# Baikal-U register map
Vendor: BAIKAL ELECTRONICS, JSC; File version: 1.0
CPU: RISC-V r0p0, little endian, no MPU, no FPU, 3 interrupt priority bits
Registers are 32-bit, read-write, reset 0x0 unless marked. A register's access mark holds for its fields unless they carry their own. Offsets are from the block's base; [hi:lo] are bit positions; {n}, {i} and the like mark numbered series.

## AHB — Advanced High-performance Bus
Base 0x15108000
0x00 PL — Arbitration Priority Master n Register
  [3:0] PL — Arbitration priority for master
0x3C EBTCOUNT — Early Burst Termination Count Register
  [9:0] EBTCOUNT — Early burst termination count
0x40 EBT_EN — Early Burst Termination Enable Register
  [0] EBT_EN — Early burst termination enable
    0=DISABLE; 1=ENABLE
0x44 EBT — Early Burst Termination Register
  [0] EBT — Early burst termination
    0=DISABLE; 1=ENABLE
0x48 DFLT_MASTER — Default Master ID Number Register
  [3:0] DFLT_MASTER — Default master ID number
0x90 VERSION_ID — Component Version ID Register

## AXI — Advanced eXtensible Interface
Base 0x1400B000
0x400 VERSION_ID — Component Version ID Register
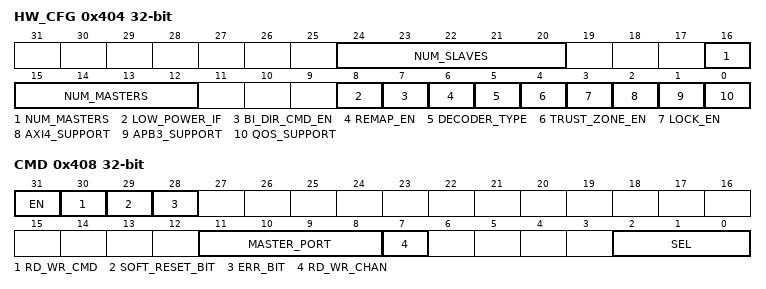
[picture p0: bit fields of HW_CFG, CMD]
0x404 HW_CFG — Hardware Configuration Register
  [24:20] NUM_SLAVES — Number of AXI slaves
  [16:12] NUM_MASTERS — Number of AXI masters
  [8] LOW_POWER_IF — Include/exclude low-power interface
    0=DISABLE; 1=ENABLE
  [7] BI_DIR_CMD_EN — Support for Enable Bi-directional Command
    0=DISABLE; 1=ENABLE
  [6] REMAP_EN — Support for Enable Remap mode
    0=DISABLE; 1=ENABLE
  [5] DECODER_TYPE — Use of External/Internal Decoder
    0=DISABLE; 1=ENABLE
  [4] TRUST_ZONE_EN — Support for Enable Trust Zone
    0=DISABLE; 1=ENABLE
  [3] LOCK_EN — Support for Enable Lock transactions
    0=DISABLE; 1=ENABLE
  [2] AXI4_SUPPORT — AXI4 features support
    0=DISABLE; 1=ENABLE
  [1] APB3_SUPPORT
    0=DISABLE; 1=ENABLE
  [0] QOS_SUPPORT
    0=DISABLE; 1=ENABLE
0x408 CMD — Command Enable Register
  [31] EN — Command enable
    0=DISABLE; 1=ENABLE
  [30] RD_WR_CMD — Read command / write command
    0=READ (Read command); 1=WRITE (Write command)
  [29] SOFT_RESET_BIT — Internal register reset
    0=DISABLE; 1=ENABLE
  [28] ERR_BIT — Error bit
    0=DISABLE; 1=ENABLE
  [11:8] MASTER_PORT — Master port ID
    {v}=Master port {v+1} (v=0..15)
  [7] RD_WR_CHAN — Read address channel / write address channel
    0=WRITE (The command is for write address channel); 1=READ (The command is for read address channel)
  [2:0] SEL — Command selection for internal registers
    0=BURST_REG_EN (BURSTINESS_REGULATOR_EN register address offset); 1=PEAK_RATE_XCT_RATE (PEAK_RATE_XCT_RATE register address offset); 2=QOS_VALUE (QOS_VALUE register address offset); 3=SLV_READY (SLV_READY register address offset)
0x40C DATA
  [31:0] DATA — Data to be written into / read from the QoS internal register

## EFLASH — Embedded Flash
Base 0xA0060000
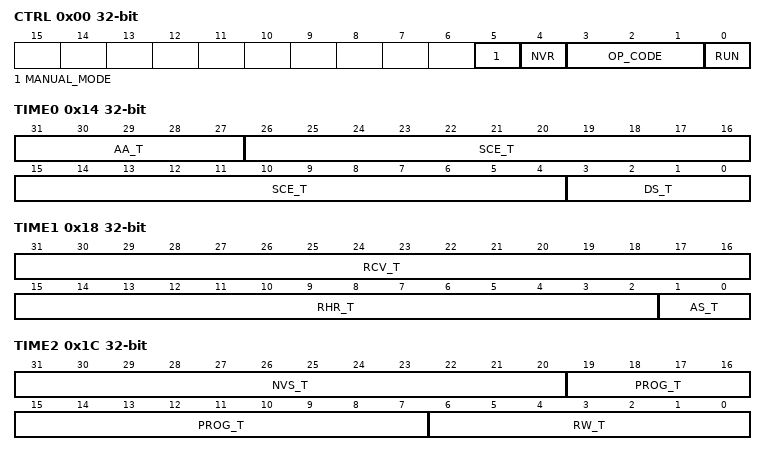
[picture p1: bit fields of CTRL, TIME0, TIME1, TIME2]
0x00 CTRL — Control register
  [5] MANUAL_MODE — Switch to manual control
    0=DISABLE; 1=ENABLE
  [4] NVR — Run OP_CODE in NVR array
    0=DISABLE; 1=ENABLE
  [3:1] OP_CODE — Operation code
    0=CFG (CFG: The flash memory configuration); 1=WRITE (WRITE: Write a word to the flash memory); 2=READ (READ: Read a word from the flash memory); 3=CHIP_ERASE (CHIP_ERASE: Chip erase); 4=BLOCK_ERASE (BLOCK_ERASE: Block erase); 5=SECTOR_ERASE (SECTOR_ERASE: Sector erase); 6=ENTER_DPD (ENTER_DPD: Enter Deep Power Down mode); 7=EXIT_DPD (EXIT_DPD: Exit Deep Power Down mode)
  [0] RUN — Run command
    0=DISABLE; 1=ENABLE
0x04 ADDR — Address register
  [15:0] ADDR — Address for a command
0x08 WDATA — Data write register
  [31:0] WDATA — Data to WRITE
0x0C RDATA — Data read register
  [31:0] RDATA — READ data
0x10 STATUS
  [0] BUSY — Busy flag
    0=DISABLE; 1=ENABLE
0x14 TIME0
  [31:27] AA_T — AE access time (max. 25ns)
  [26:4] SCE_T — Chip Erase time (8ms to 10ms)
  [3:0] DS_T — Data to PROG2 High setup time (min. 15ns)
0x18 TIME1
  [31:16] RCV_T — Erase recovery time (min. 50us)
  [15:2] RHR_T — PORb High to any operation time (min. 10us)
  [1:0] AS_T — Address and ARRDN/NVR setup time (min. 2ns)
0x1C TIME2
  [31:20] NVS_T — Program First AE / Sector Erase AE / Block Erase AE to WEb setup time (min. 4us)
  [19:7] PROG_T — Program time (8us to 10us)
  [6:0] RW_T — Latency to next operation after PROG/ERASE Low time (min. 100ns)
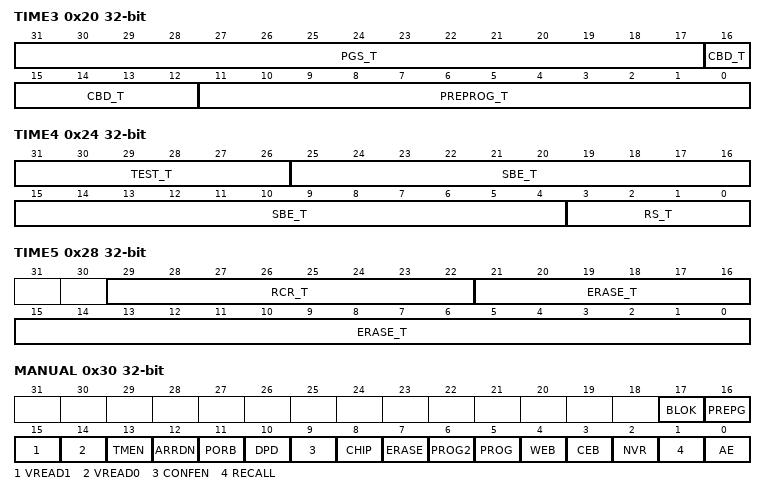
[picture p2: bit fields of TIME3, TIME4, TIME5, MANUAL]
0x20 TIME3
  [31:17] PGS_T — WEb Low to PROG2 High setup time (min. 20us)
  [16:12] CBD_T — Configuration register data setup time (max. 20ns)
  [11:0] PREPROG_T — Pre-Program time (2.5us to 3.5us)
0x24 TIME4
  [31:26] TEST_T — Test mode inputs setup time (min. 50ns)
  [25:4] SBE_T — Block Erase time (4ms to 6ms)
  [3:0] RS_T — RECALL to AE time (min. 10ns)
0x28 TIME5
  [29:22] RCR_T — Recall Read cycle time (min. 200ns)
  [21:0] ERASE_T — Sector Erase time (3.2ms to 4ms)
0x2C TIME6
  [12:0] PREPGS_T — Exit Pre-Program to PROG2 High setup time (min. 5us)
0x30 MANUAL — Manual control register
  [all] fields
    0=DISABLE; 1=ENABLE
  [17] BLOK — BLOK input control
  [16] PREPG — PREPG input control
  [15] VREAD1 — VREAD1 input control
  [14] VREAD0 — VREAD0 input control
  [13] TMEN — TMEN input control
  [12] ARRDN — ARRDN input control
  [11] PORB — PORB input control
  [10] DPD — DPD input control
  [9] CONFEN — CONFEN input control
  [8] CHIP — CHIP input control
  [7] ERASE — ERASE input control
  [6] PROG2 — PROG2 input control
  [5] PROG — PROG input control
  [4] WEB — WEB input control
  [3] CEB — CEB input control
  [2] NVR — NVR input control
  [1] RECALL — RECALL input control
  [0] AE — AE input control
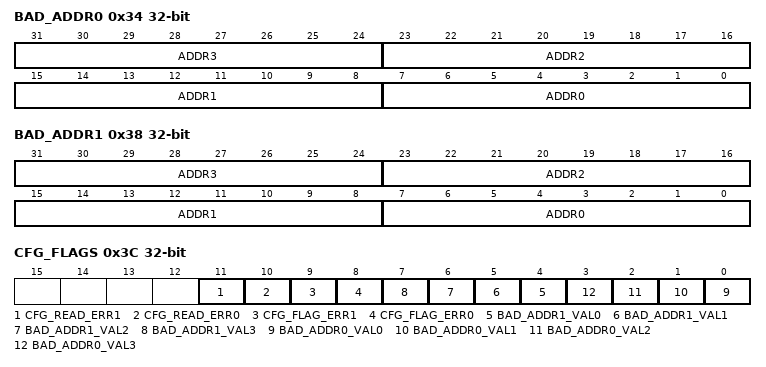
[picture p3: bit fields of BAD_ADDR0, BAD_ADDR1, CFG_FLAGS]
0x34 BAD_ADDR0 — Flash 0 bad sectors address register
  [8n+7:8n] ADDR{n} (n=0..3) — EFLASH 0 bad sector address {n}
0x38 BAD_ADDR1 — Flash 1 bad sectors address register
  [8n+7:8n] ADDR{n} (n=0..3) — EFLASH 1 bad sector address {n}
0x3C CFG_FLAGS — Flash configuration flags register
  [all] fields
    0=DISABLE; 1=ENABLE
  [11] CFG_READ_ERR1 — EFLASH 1 configuration register error
  [10] CFG_READ_ERR0 — EFLASH 0 configuration register error
  [9] CFG_FLAG_ERR1 — EFLASH 1 configuration flag error
  [8] CFG_FLAG_ERR0 — EFLASH 0 configuration flag error
  [n+4] BAD_ADDR1_VAL{n} (n=0..3) — EFLASH 1 bad sector address {n} validity flag
  [n] BAD_ADDR0_VAL{n} (n=0..3) — EFLASH 0 bad sector address {n} validity flag
{0x40+4i} NVR_DIS{i} (i=0..15) — NVR register {i}
